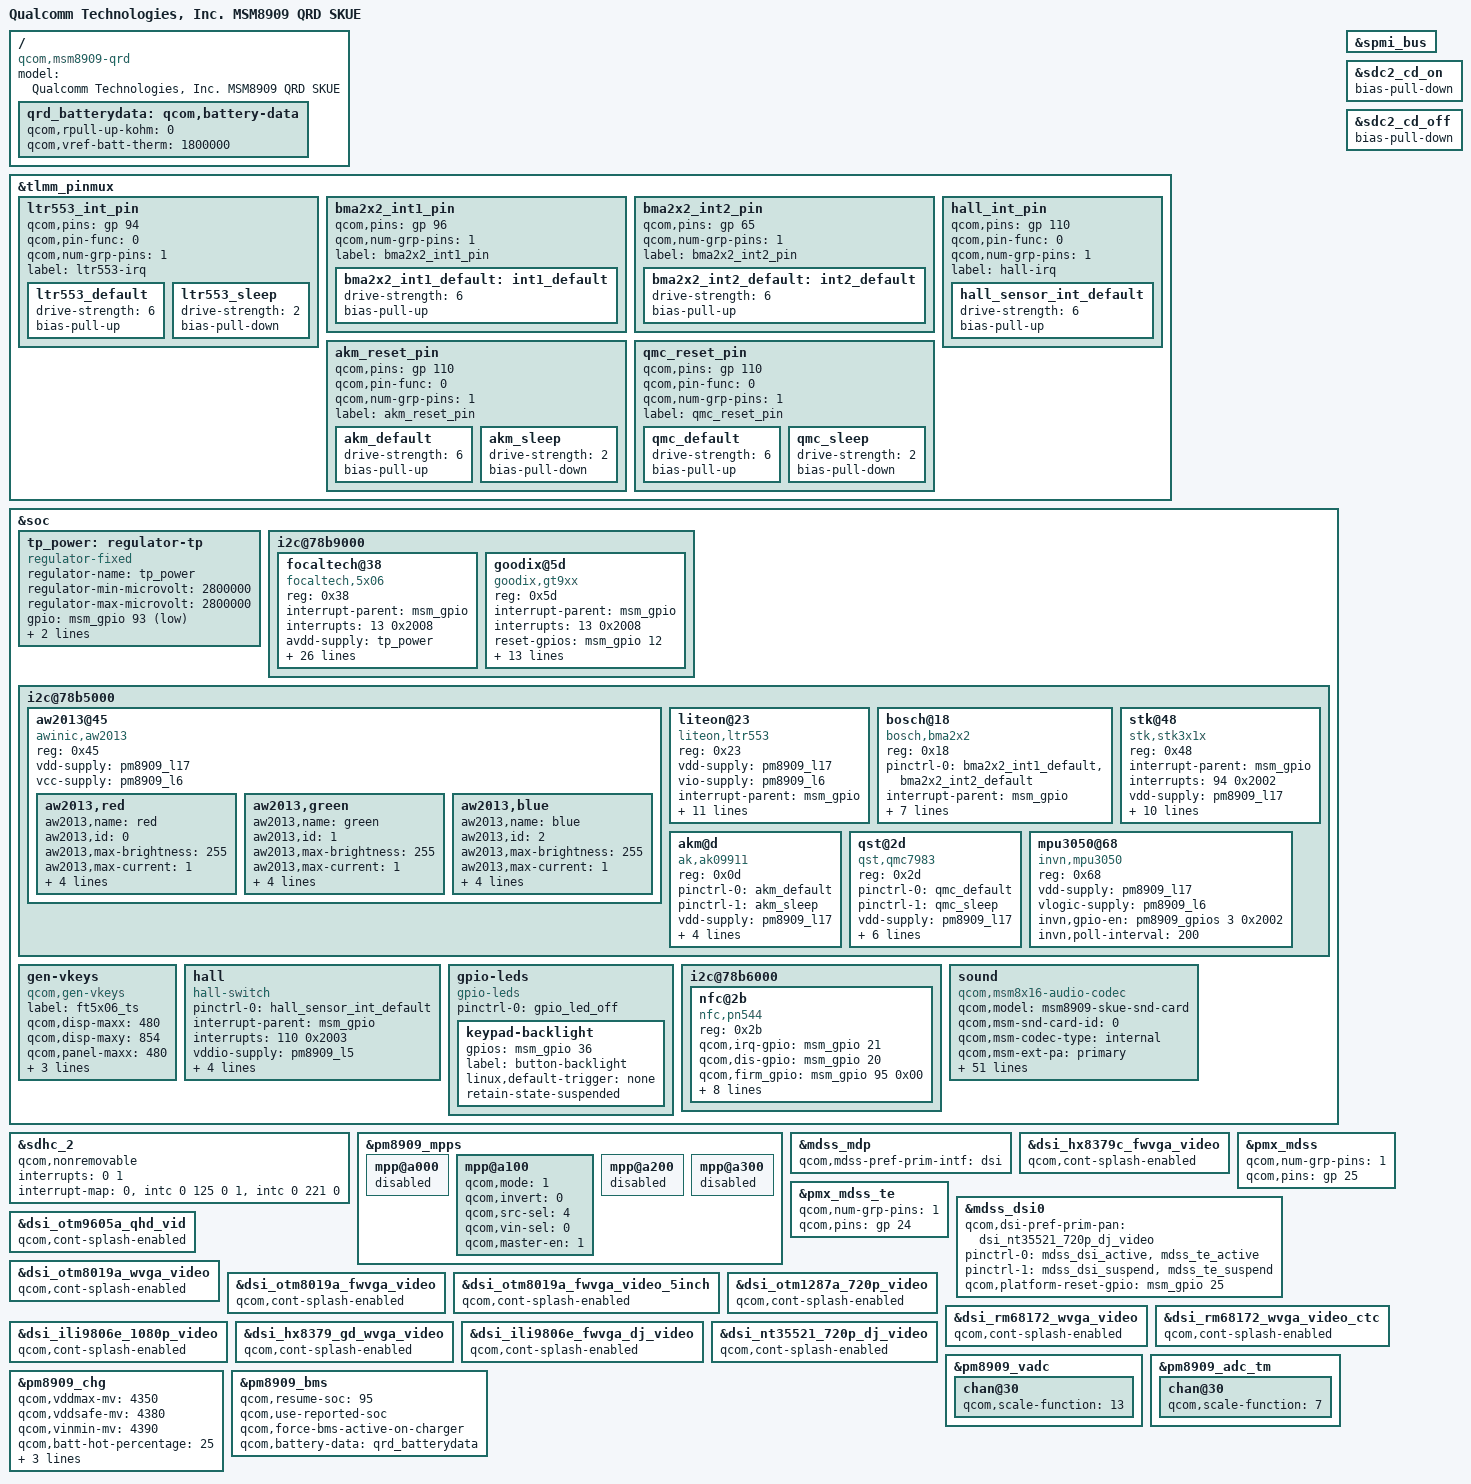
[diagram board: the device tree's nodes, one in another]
/**********uniscope-driver-modify-file-on-qualcomm-platform*****************/
/* Copyright (c) 2014-2015, The Linux Foundation. All rights reserved.
 *
 * This program is free software; you can redistribute it and/or modify
 * it under the terms of the GNU General Public License version 2 and
 * only version 2 as published by the Free Software Foundation.
 *
 * This program is distributed in the hope that it will be useful,
 * but WITHOUT ANY WARRANTY; without even the implied warranty of
 * MERCHANTABILITY or FITNESS FOR A PARTICULAR PURPOSE.  See the
 * GNU General Public License for more details.
 */

#include "msm8909-qrd.dtsi"
#include "msm8909-camera-sensor-skue.dtsi"

/ {
	model = "Qualcomm Technologies, Inc. MSM8909 QRD SKUE";
	compatible = "qcom,msm8909-qrd", "qcom,msm8909", "qcom,qrd";
};

&tlmm_pinmux {
	ltr553_int_pin {
		qcom,pins = <&gp 94>;
		qcom,pin-func = <0>;
		qcom,num-grp-pins = <1>;
		label = "ltr553-irq";
		ltr553_default: ltr553_default {
			drive-strength = <6>;
			bias-pull-up;
		};
		ltr553_sleep: ltr553_sleep {
			drive-strength = <2>;
			bias-pull-down;
		};

	};

	bma2x2_int1_pin {
		qcom,pins = <&gp 96>;
		qcom,num-grp-pins = <1>;
		label = "bma2x2_int1_pin";
		bma2x2_int1_default: int1_default {
			  drive-strength = <6>;
			  bias-pull-up;
		};
	};

	bma2x2_int2_pin {
		qcom,pins = <&gp 65>;
		qcom,num-grp-pins = <1>;
		label = "bma2x2_int2_pin";
		bma2x2_int2_default: int2_default {
			  drive-strength = <6>;
			  bias-pull-up;
		};
	};

	hall_int_pin {
		qcom,pins = <&gp 110>; /* JZZ(zhizhang)@uniscope_drv for keyled use gpio36 20150210 */
		qcom,pin-func = <0>;
		qcom,num-grp-pins = <1>;
		label = "hall-irq";
		hall_sensor_int_default: hall_sensor_int_default {
			drive-strength = <6>;
			bias-pull-up;
		};
	};
	/* Added by JZZ(zhizhang)@uniscope_drv for sensor device tree 20150210 begin */
	akm_reset_pin {
		qcom,pins = <&gp 110>;
		qcom,pin-func = <0>;
		qcom,num-grp-pins = <1>;
		label = "akm_reset_pin";
		akm_default: akm_default {
			drive-strength = <6>;
			bias-pull-up;
		};
		akm_sleep: akm_sleep {
			drive-strength = <2>;
			bias-pull-down;
		};
	};
	/* Added by JZZ(zhizhang)@uniscope_drv for sensor device tree 20150210 end */
	/*kangyan@uni_drv add qmc7983 sleep protect begin*/
	qmc_reset_pin {
		qcom,pins = <&gp 110>;
		qcom,pin-func = <0>;
		qcom,num-grp-pins = <1>;
		label = "qmc_reset_pin";
		qmc_default: qmc_default {
			drive-strength = <6>;
			bias-pull-up;
		};
		qmc_sleep: qmc_sleep {
			drive-strength = <2>;
			bias-pull-down;
		};
	};
	/*kangyan@uni_drv add qmc7983 sleep protect end*/
};

&soc {
	/* <JZZ(zhizhang)>@uniscope_drv 20140701 for adding TP tp_power begin */
	tp_power: regulator-tp {
		compatible = "regulator-fixed";
		regulator-name = "tp_power";
		regulator-min-microvolt = <2800000>;
		regulator-max-microvolt = <2800000>;
		gpio = <&msm_gpio 93 0x01>;
		startup-delay-us = <20000>;
		enable-active-high;
	};
	/* <JZZ(zhizhang)>@uniscope_drv 20140701 for adding TP tp_power end */
	i2c@78b9000 { /* BLSP1 QUP5 */
		focaltech@38 {
				compatible = "focaltech,5x06";
				reg = <0x38>;
				interrupt-parent = <&msm_gpio>; 
				interrupts = <13 0x2008>;  
				avdd-supply =<&tp_power>;
				/*liguowei@uni	20150107  pinctrl  used by touchscreen begin */
				pinctrl-names = "pmx_ts_active","pmx_ts_suspend","pmx_ts_release";
				pinctrl-0 = <&ts_int_active &ts_reset_active>;
				pinctrl-1 = <&ts_int_suspend &ts_reset_suspend>;
				pinctrl-2 = <&ts_release>;
				/*liguowei@uni	20150107  pinctrl  used by touchscreen end */
				focaltech,name = "FT5406DQ9";
				focaltech,family-id = <0x55>;
				focaltech,reset-gpio = <&msm_gpio 12 0x0>;
				focaltech,irq-gpio = <&msm_gpio 13 0x2008>;
				focaltech,display-coords = <0 0 480 854>;
				focaltech,panel-coords = <0 0 500 854>;
				focaltech,button-map= <139 172 158>;
				focaltech,no-force-update;
				focaltech,i2c-pull-up;
				focaltech,fw-vkey-support;
				focaltech,group-id = <1>;
				focaltech,hard-reset-delay-ms = <20>;
				focaltech,soft-reset-delay-ms = <150>;
				focaltech,num-max-touches = <5>;
				focaltech,fw-name = "ft_8916_qrd_fw.bin";
				focaltech,fw-delay-aa-ms = <50>;
				focaltech,fw-delay-55-ms = <30>;
				focaltech,fw-upgrade-id1 = <0x79>;
				focaltech,fw-upgrade-id2 = <0x03>;
				focaltech,fw-delay-readid-ms = <10>;
				focaltech,fw-delay-era-flsh-ms = <2000>;
				focaltech,fw-auto-cal;
				focaltech,ignore-id-check;
			};

		
	/* JZZ(zhizhang)@uniscope_drv 20150206 add tp dtsi begin */
		goodix@5d {
			compatible = "goodix,gt9xx";
			reg = <0x5d>;
			interrupt-parent = <&msm_gpio>; 
			interrupts = <13 0x2008>;  
			reset-gpios = <&msm_gpio 12 0x00>;
			interrupt-gpios = <&msm_gpio 13 0x00>;
			avdd-supply =<&tp_power>;
			/*zhangbing@uniscope_drv20151013 TP gt9157 interrupt voltage abnormal(lower than normal) begin*/
			pinctrl-names = "pmx_ts_active","pmx_ts_suspend";
			pinctrl-0 = <&ts_int_active &ts_reset_active>;
			pinctrl-1 = <&ts_int_suspend &ts_reset_suspend>;
			/*zhangbing@uniscope_drv20151013 TP gt9157 interrupt voltage abnormal(lower than normal) end*/
			goodix,panel-coords = <0 0 480 854>;
			goodix,display-coords = <0 0 480 854>;
			goodix,button-map= <158 102 139>;
			goodix,product-id = "915";
			goodix,cfg-data0 = [
				41 E0 01 20 03 0A 05 C1 01 08 
				28 05 50 32 03 05 00 00 FF 7F 
				00 00 00 00 00 00 14 88 27 0A 
				2C 2E B5 06 00 00 01 9B 33 11 
				3C 01 00 00 00 03 64 32 00 00 
				CA 1E 5A 94 C5 02 07 00 00 04 
				A8 21 00 88 29 00 6D 34 00 58 
				41 00 48 51 00 48 0F 2F 47 00 
				F7 40 30 FF FF 27 00 00 00 00 
				00 00 00 00 00 00 00 00 00 00 
				00 00 00 00 00 00 00 19 00 00 
				46 00 08 0A 0C 0E 10 12 14 16 
				18 1A 00 00 00 00 00 00 00 00 
				00 00 00 00 00 00 00 00 00 00 
				00 00 28 24 22 20 1F 1E 1D 0C 
				0A 08 06 05 04 02 00 00 00 00 
				00 00 00 00 00 00 00 00 00 00 
				00 FF FF FF FF FF FF FF FF FF 
				FF FF FF FF B4 01];
			goodix,cfg-data1 = [
				41 E0 01 20 03 0A 05 C1 01 08 
				28 05 50 32 03 05 00 00 FF 7F 
				00 00 00 00 00 00 14 88 27 0A 
				2C 2E B5 06 00 00 01 9B 33 11 
				3C 01 00 00 00 03 64 32 00 00 
				CA 1E 5A 94 C5 02 07 00 00 04 
				A8 21 00 88 29 00 6D 34 00 58 
				41 00 48 51 00 48 0F 2F 47 00 
				F7 40 30 FF FF 27 00 00 00 00 
				00 00 00 00 00 00 00 00 00 00 
				00 00 00 00 00 00 00 19 00 00 
				46 00 08 0A 0C 0E 10 12 14 16 
				18 1A 00 00 00 00 00 00 00 00 
				00 00 00 00 00 00 00 00 00 00 
				00 00 28 24 22 20 1F 1E 1D 0C 
				0A 08 06 05 04 02 00 00 00 00 
				00 00 00 00 00 00 00 00 00 00 
				00 FF FF FF FF FF FF FF FF FF 
				FF FF FF FF B4 01];
			goodix,fw_name = "gtp_fw.bin";
		};
	/* JZZ(zhizhang)@uniscope_drv 20150206 add TP dtsi end */		
	};

	i2c@78b5000 { /* BLSP1 QUP1 */
		aw2013@45 {
			compatible = "awinic,aw2013";
			reg = <0x45>;
			vdd-supply = <&pm8909_l17>;
			vcc-supply = <&pm8909_l6>;

			aw2013,red {
				aw2013,name = "red";
				aw2013,id = <0>;
				aw2013,max-brightness = <255>;
				aw2013,max-current = <1>;
				aw2013,rise-time-ms = <2>;
				aw2013,hold-time-ms = <1>;
				aw2013,fall-time-ms = <2>;
				aw2013,off-time-ms = <1>;
			};

			aw2013,green {
				aw2013,name = "green";
				aw2013,id = <1>;
				aw2013,max-brightness = <255>;
				aw2013,max-current = <1>;
				aw2013,rise-time-ms = <2>;
				aw2013,hold-time-ms = <1>;
				aw2013,fall-time-ms = <2>;
				aw2013,off-time-ms = <1>;
			};

			aw2013,blue {
				aw2013,name = "blue";
				aw2013,id = <2>;
				aw2013,max-brightness = <255>;
				aw2013,max-current = <1>;
				aw2013,rise-time-ms = <2>;
				aw2013,hold-time-ms = <1>;
				aw2013,fall-time-ms = <2>;
				aw2013,off-time-ms = <1>;
			};
		};
	};

	gen-vkeys {
		compatible = "qcom,gen-vkeys";
		label = "ft5x06_ts";
		qcom,disp-maxx = <480>;
		qcom,disp-maxy = <854>;
		qcom,panel-maxx = <480>;
		qcom,panel-maxy = <946>;
		qcom,key-codes = <139 172 158>;
		qcom,y-offset = <0>;
	};

	i2c@78b5000 { /* BLSP1 QUP1 */
		liteon@23 {
			compatible = "liteon,ltr553";
			reg = <0x23>;
			vdd-supply = <&pm8909_l17>;
			vio-supply = <&pm8909_l6>;
			interrupt-parent = <&msm_gpio>;
			interrupts = <94 0x2002>;
			pinctrl-names = "default","sleep";
			pinctrl-0 = <&ltr553_default>;
			pinctrl-1 = <&ltr553_sleep>;
			liteon,irq-gpio = <&msm_gpio 94 0x2002>;
			liteon,als-ps-persist = <0>;
			liteon,ps-led = <0x7f>;
			liteon,ps-pulses = <4>;
			liteon,wakeup-threshold = <4>;
			liteon,als-integration-time = <0>;
			liteon,ps-distance-table = <1376 566 343 287 200 170 155>;
		};

		bosch@18 { /* Accelerometer sensor */
			compatible = "bosch,bma2x2";
			reg = <0x18>;
			pinctrl-names = "default";
			pinctrl-0 = <&bma2x2_int1_default &bma2x2_int2_default>;
			interrupt-parent = <&msm_gpio>;
			interrupts = <96 0x2002>;
			vdd-supply = <&pm8909_l17>;
			vio-supply = <&pm8909_l6>;
			bosch,init-interval = <200>;
			bosch,place = <4>;
			bosch,gpio-int1 = <&msm_gpio 96 0x2002>;
			bosch,gpio-int2 = <&msm_gpio 65 0x2002>;
		};

		/*liguowei@uniscope 20140910 add stk3x1x begin*/
		stk@48 {
			compatible = "stk,stk3x1x";
			reg = <0x48>;
			interrupt-parent = <&msm_gpio>;
			interrupts = <94 0x2002>;
			vdd-supply = <&pm8909_l17>;
			vio-supply = <&pm8909_l6>;
			stk,irq-gpio = <&msm_gpio 94 0x2002>;
			stk,transmittance = <4092>;
			stk,state-reg = <0x00>;
			stk,psctrl-reg = <0x31>;
			stk,alsctrl-reg = <0x39>;
			stk,ledctrl-reg = <0xBF>;
			stk,wait-reg = <0x09>;
			stk,ps-thdh = <100>;
			stk,ps-thdl = <50>;
		};
		//liguowei@uniscope 20140910 add stk3x1x end	
		/* Added by JZZ(zhizhang)@uniscope_drv for sensor device tree 20150210 begin */
		akm@d {
			compatible = "ak,ak09911";
			reg = <0x0d>;
			pinctrl-names = "default","sleep";
			pinctrl-0 = <&akm_default>;
			pinctrl-1 = <&akm_sleep>;
			vdd-supply = <&pm8909_l17>;
			vio-supply = <&pm8909_l6>;
			akm,layout = <0x5>;
			akm,gpio_rstn = <&msm_gpio 99 0x0>;
			akm,auto-report;
		};
		//kangyan@uniscope_drv add QMC7983 sensor 20150511
		qst@2d { /* Magnetic field sensor */
			compatible = "qst,qmc7983";
			reg = <0x2d>;
			pinctrl-names = "default","sleep";
			pinctrl-0 = <&qmc_default>;
			pinctrl-1 = <&qmc_sleep>;
			vdd-supply = <&pm8909_l17>;
			vio-supply = <&pm8909_l6>;
			qst,dir = "obverse-x-axis-forward";
			qst,gpio_rstn = <&msm_gpio 110 0x0>;
			qst,layout = <0x8>;
			qst,auto-report;
			qst,delay_ms = <10>;
		};
		mpu3050@68 { /* Gyroscope and accelerometer sensor combo */
			compatible = "invn,mpu3050";
			reg = <0x68>;		
			vdd-supply = <&pm8909_l17>;
			vlogic-supply = <&pm8909_l6>;
			invn,gpio-en = <&pm8909_gpios 3 0x2002>;
			invn,poll-interval = <200>;
		};
		/* Added by JZZ(zhizhang)@uniscope_drv for sensor device tree 20150210 end */
	};

	hall {
		compatible = "hall-switch";
		pinctrl-names = "default";
		pinctrl-0 = <&hall_sensor_int_default>;
		interrupt-parent = <&msm_gpio>;
		interrupts = <110 0x2003>;   /* JZZ(zhizhang)@uniscope_drv for keyled use gpio36 20150210 */
		vddio-supply = <&pm8909_l5>;
		linux,gpio-int = <&msm_gpio 110 0x1>;  /* JZZ(zhizhang)@uniscope_drv for keyled use gpio36 20150210 */
		linux,wakeup;
		linux,min-uv = <1650000>;
		linux,max-uv = <3300000>;
	};
	
	/* JZZ(zhizhang)@uniscope_drv 20150317 add keypad led control begin */
	gpio-leds {
		compatible = "gpio-leds";
		status = "okay";
		pinctrl-names = "default";
		pinctrl-0 = <&gpio_led_off>;

		keypad-backlight {
			gpios = <&msm_gpio 36 0>;
			label = "button-backlight";
			linux,default-trigger = "none";
			retain-state-suspended;
		};
	};
	/* JZZ(zhizhang)@uniscope_drv 20150317 add keypad led control end */

	//JZZ(zhizhang)@uni_drv 20150410 add nfc pn547 driver begin 
	i2c@78b6000 { /* BLSP1 QUP2 */
		nfc@2b {
			compatible = "nfc,pn544";
			reg = <0x2b>;
			qcom,irq-gpio = <&msm_gpio 21 0x00>;
			qcom,dis-gpio = <&msm_gpio 20 0x00>;
			qcom,firm_gpio= <&msm_gpio 95 0x00>;
			qcom,clk-src = "BBCLK2";
			interrupt-parent = <&msm_gpio>;
			interrupts = <21 0>;
			interrupt-names = "nfc_irq";
			pinctrl-names = "nfc_active","nfc_suspend";
			pinctrl-0 = <&nfc_int_active &nfc_disable_active>;
			pinctrl-1 = <&nfc_int_suspend &nfc_disable_suspend>;
			qcom,clk-gpio = <&pm8909_gpios 2 0>;
			clocks = <&clock_rpm clk_bb_clk2_pin>;
			clock-names = "ref_clk";
		};
	};
	//JZZ(zhizhang)@uni_drv 20150410 add nfc pn547 driver end

	sound {
		compatible = "qcom,msm8x16-audio-codec";
		qcom,model = "msm8909-skue-snd-card";
		qcom,msm-snd-card-id = <0>;
		qcom,msm-codec-type = "internal";
		qcom,msm-ext-pa = "primary";
		qcom,msm-mclk-freq = <9600000>;
		//kangyan@uni_drv 20150319 enable spk and micbias
		qcom,msm-spk-ext-pa = <&msm_gpio 98 0>;
		qcom,msm-mbhc-hphl-swh = <1>;
		qcom,msm-mbhc-gnd-swh = <0>;
		qcom,msm-hs-micbias-type = "internal";
		qcom,msm-micbias1-ext-cap;
		qcom,msm-micbias2-ext-cap;
		qcom,audio-routing =
			"RX_BIAS", "MCLK",
			"SPK_RX_BIAS", "MCLK",
			"INT_LDO_H", "MCLK",
			"MIC BIAS Internal1", "Handset Mic",
			"MIC BIAS Internal2", "Headset Mic",
			"MIC BIAS Internal3", "Secondary Mic",
			"AMIC1", "MIC BIAS Internal1",
			"AMIC2", "MIC BIAS Internal2",
			"AMIC3", "MIC BIAS Internal3";			
		pinctrl-names = "cdc_lines_act",
				"cdc_lines_sus";
		pinctrl-0 = <&cdc_pdm_lines_act>;
		pinctrl-1 = <&cdc_pdm_lines_sus>;
		asoc-platform = <&pcm0>, <&pcm1>, <&voip>, <&voice>,
				<&loopback>, <&compress>, <&hostless>,
				<&afe>, <&lsm>, <&routing>, <&lpa>,
				<&voice_svc>;
		asoc-platform-names = "msm-pcm-dsp.0", "msm-pcm-dsp.1",
				"msm-voip-dsp", "msm-pcm-voice", "msm-pcm-loopback",
				"msm-compress-dsp", "msm-pcm-hostless", "msm-pcm-afe",
				"msm-lsm-client", "msm-pcm-routing", "msm-pcm-lpa",
				"msm-voice-svc";
		asoc-cpu = <&dai_pri_auxpcm>, <&dai_hdmi>,
				<&dai_mi2s0>, <&dai_mi2s1>, <&dai_mi2s2>, <&dai_mi2s3>,
				<&sb_0_rx>, <&sb_0_tx>, <&sb_1_rx>, <&sb_1_tx>,
				<&sb_3_rx>, <&sb_3_tx>, <&sb_4_rx>, <&sb_4_tx>,
				<&bt_sco_rx>, <&bt_sco_tx>, <&int_fm_rx>, <&int_fm_tx>,
				<&afe_pcm_rx>, <&afe_pcm_tx>, <&afe_proxy_rx>, <&afe_proxy_tx>,
				<&incall_record_rx>, <&incall_record_tx>, <&incall_music_rx>,
				<&incall_music_2_rx>;
		asoc-cpu-names = "msm-dai-q6-auxpcm.1", "msm-dai-q6-hdmi.8",
				"msm-dai-q6-mi2s.0", "msm-dai-q6-mi2s.1",
				"msm-dai-q6-mi2s.2", "msm-dai-q6-mi2s.3",
				"msm-dai-q6-dev.16384",	"msm-dai-q6-dev.16385",
				"msm-dai-q6-dev.16386", "msm-dai-q6-dev.16387",
				"msm-dai-q6-dev.16390", "msm-dai-q6-dev.16391",
				"msm-dai-q6-dev.16392",	"msm-dai-q6-dev.16393",
				"msm-dai-q6-dev.12288", "msm-dai-q6-dev.12289",
				"msm-dai-q6-dev.12292", "msm-dai-q6-dev.12293",
				"msm-dai-q6-dev.224", "msm-dai-q6-dev.225",
				"msm-dai-q6-dev.241", "msm-dai-q6-dev.240",
				"msm-dai-q6-dev.32771", "msm-dai-q6-dev.32772",
				"msm-dai-q6-dev.32773", "msm-dai-q6-dev.32770";
		asoc-codec = <&stub_codec>, <&pm8909_conga_dig>;
		asoc-codec-names = "msm-stub-codec.1", "tombak_codec";
	};
};

&spmi_bus {
	/* JZZ(zhizhang)@uniscope_drv 20150317 add keypad led control begin */
	/*
	qcom,pm8909@0 {
		qcom,leds@a300 {
			status = "okay";
			qcom,led_mpp_4 {
				label = "mpp";
				linux,name = "button-backlight";
				linux,default-trigger = "none";
				qcom,default-state = "off";
				qcom,max-current = <40>;
				qcom,current-setting = <5>;
				qcom,id = <6>;
				qcom,mode = "manual";
				qcom,source-sel = <1>;
				qcom,mode-ctrl = <0x60>;
			};
		};
	};
	*/
	/* JZZ(zhizhang)@uniscope_drv 20150317 add keypad led control end */
};

&sdc2_cd_on {
        /delete-property/ bias-pull-up;
        bias-pull-down;
};

&sdc2_cd_off {
        /delete-property/ bias-disable;
        bias-pull-down;
};

&sdhc_2 {
        qcom,nonremovable;

        interrupts = <0 1>;
        interrupt-map = <0 &intc 0 125 0
                1 &intc 0 221 0>;
        interrupt-names = "hc_irq", "pwr_irq";
        /delete-property/ cd-gpios;
};

&pm8909_mpps {
	mpp@a000 { /* MPP 1 */
		/* VDD_PX */
		status = "disabled";
	};

	mpp@a100 { /* MPP 2 */
		/* Backlight PWM */
		qcom,mode = <1>;		/* Digital output */
		qcom,invert = <0>;		/* Disable invert */
		qcom,src-sel = <4>;		/* DTEST1 */
		qcom,vin-sel = <0>;		/* VPH_PWR */
		qcom,master-en = <1>;		/* Enable MPP */
	};

	mpp@a200 { /* MPP 3 */
		/* VREF DAC */
		status = "disabled";
	};

	mpp@a300 { /* MPP 4 */
		/* HR LED */
		status = "disabled";
	};
};

#include "dsi-panel-hx8379c-fwvga-video.dtsi"

&mdss_mdp {
	qcom,mdss-pref-prim-intf = "dsi";
};

&dsi_hx8379c_fwvga_video {
	qcom,cont-splash-enabled;
};

&pmx_mdss {
	qcom,num-grp-pins = <1>;
	qcom,pins = <&gp 25>;
};

&pmx_mdss_te {
	qcom,num-grp-pins = <1>;
	qcom,pins = <&gp 24>;
};

&mdss_dsi0 {
	qcom,dsi-pref-prim-pan = <&dsi_hx8379c_fwvga_video>;
	pinctrl-names = "mdss_default", "mdss_sleep";
	pinctrl-0 = <&mdss_dsi_active &mdss_te_active>;
	pinctrl-1 = <&mdss_dsi_suspend &mdss_te_suspend>;

	qcom,platform-reset-gpio = <&msm_gpio 25 0>;
};

/* JZZ(zhizhang)@uniscope_drv 20140620 for adjusting otm9605a-qhd lcd begin */
#include "dsi-panel-otm9605a-qhd-video.dtsi"
&mdss_mdp {
	qcom,mdss-pref-prim-intf = "dsi";
};

&dsi_otm9605a_qhd_vid {
	qcom,cont-splash-enabled;
};

&pmx_mdss {
	qcom,num-grp-pins = <1>;
	qcom,pins = <&gp 25>;
};

&pmx_mdss_te {
	qcom,num-grp-pins = <1>;
	qcom,pins = <&gp 24>;
};

&mdss_dsi0 {
	qcom,dsi-pref-prim-pan = <&dsi_otm9605a_qhd_vid>;
	pinctrl-names = "mdss_default", "mdss_sleep";
	pinctrl-0 = <&mdss_dsi_active &mdss_te_active>;
	pinctrl-1 = <&mdss_dsi_suspend &mdss_te_suspend>;

	qcom,platform-reset-gpio = <&msm_gpio 25 0>;
};

#include "dsi-panel-otm8019a-wvga-video.dtsi"
&mdss_mdp {
	qcom,mdss-pref-prim-intf = "dsi";
};

&dsi_otm8019a_wvga_video {
	qcom,cont-splash-enabled;
};

&pmx_mdss {
	qcom,num-grp-pins = <1>;
	qcom,pins = <&gp 25>;
};

&pmx_mdss_te {
	qcom,num-grp-pins = <1>;
	qcom,pins = <&gp 24>;
};

&mdss_dsi0 {
	qcom,dsi-pref-prim-pan = <&dsi_otm8019a_wvga_video>;
	pinctrl-names = "mdss_default", "mdss_sleep";
	pinctrl-0 = <&mdss_dsi_active &mdss_te_active>;
	pinctrl-1 = <&mdss_dsi_suspend &mdss_te_suspend>;

	qcom,platform-reset-gpio = <&msm_gpio 25 0>;
};

/*zhangbing@uniscope drv 20150624 add L510 LCD OTM8019A FWVGA begin*/
#include "dsi-panel-otm8019a-fwvga-video.dtsi"
&mdss_mdp {
	qcom,mdss-pref-prim-intf = "dsi";
};

&dsi_otm8019a_fwvga_video {
	qcom,cont-splash-enabled;
};

&pmx_mdss {
	qcom,num-grp-pins = <1>;
	qcom,pins = <&gp 25>;
};

&pmx_mdss_te {
	qcom,num-grp-pins = <1>;
	qcom,pins = <&gp 24>;
};

&mdss_dsi0 {
	qcom,dsi-pref-prim-pan = <&dsi_otm8019a_fwvga_video>;
	pinctrl-names = "mdss_default", "mdss_sleep";
	pinctrl-0 = <&mdss_dsi_active &mdss_te_active>;
	pinctrl-1 = <&mdss_dsi_suspend &mdss_te_suspend>;

	qcom,platform-reset-gpio = <&msm_gpio 25 0>;
};
/*zhangbing@uniscope drv 20150624 add L510 LCD OTM8019A FWVGA end*/

/*zhangbing@uniscope drv 20150624 add L510 LCD OTM8019A FWVGA 5INCH begin*/
#include "dsi-panel-otm8019a-fwvga-video-5inch.dtsi"
&mdss_mdp {
	qcom,mdss-pref-prim-intf = "dsi";
};

&dsi_otm8019a_fwvga_video_5inch {
	qcom,cont-splash-enabled;
};

&pmx_mdss {
	qcom,num-grp-pins = <1>;
	qcom,pins = <&gp 25>;
};

&pmx_mdss_te {
	qcom,num-grp-pins = <1>;
	qcom,pins = <&gp 24>;
};

&mdss_dsi0 {
	qcom,dsi-pref-prim-pan = <&dsi_otm8019a_fwvga_video_5inch>;
	pinctrl-names = "mdss_default", "mdss_sleep";
	pinctrl-0 = <&mdss_dsi_active &mdss_te_active>;
	pinctrl-1 = <&mdss_dsi_suspend &mdss_te_suspend>;

	qcom,platform-reset-gpio = <&msm_gpio 25 0>;
};
/*zhangbing@uniscope drv 20150624 add L510 LCD OTM8019A FWVGA 5INCH end*/

/*zhangbing@uniscope drv 20150624 add L510 LCD OTM1287A 720p begin*/
#include "dsi-panel-otm1287a-720p-video.dtsi"
&mdss_mdp {
	qcom,mdss-pref-prim-intf = "dsi";
};

&dsi_otm1287a_720p_video {
	qcom,cont-splash-enabled;
};

&pmx_mdss {
	qcom,num-grp-pins = <1>;
	qcom,pins = <&gp 25>;
};

&pmx_mdss_te {
	qcom,num-grp-pins = <1>;
	qcom,pins = <&gp 24>;
};

&mdss_dsi0 {
	qcom,dsi-pref-prim-pan = <&dsi_otm1287a_720p_video>;
	pinctrl-names = "mdss_default", "mdss_sleep";
	pinctrl-0 = <&mdss_dsi_active &mdss_te_active>;
	pinctrl-1 = <&mdss_dsi_suspend &mdss_te_suspend>;

	qcom,platform-reset-gpio = <&msm_gpio 25 0>;
};
/*zhangbing@uniscope drv 20150624 add L510 LCD OTM1287A 720p end*/

#include "dsi-panel-rm68172-wvga-video.dtsi"
&mdss_mdp {
	qcom,mdss-pref-prim-intf = "dsi";
};

&dsi_rm68172_wvga_video {
	qcom,cont-splash-enabled;
};

&pmx_mdss {
	qcom,num-grp-pins = <1>;
	qcom,pins = <&gp 25>;
};

&pmx_mdss_te {
	qcom,num-grp-pins = <1>;
	qcom,pins = <&gp 24>;
};

&mdss_dsi0 {
	qcom,dsi-pref-prim-pan = <&dsi_rm68172_wvga_video>;
	pinctrl-names = "mdss_default", "mdss_sleep";
	pinctrl-0 = <&mdss_dsi_active &mdss_te_active>;
	pinctrl-1 = <&mdss_dsi_suspend &mdss_te_suspend>;

	qcom,platform-reset-gpio = <&msm_gpio 25 0>;
};


#include "dsi-panel-rm68172-wvga-video_ctc.dtsi"
&mdss_mdp {
	qcom,mdss-pref-prim-intf = "dsi";
};

&dsi_rm68172_wvga_video_ctc {
	qcom,cont-splash-enabled;
};

&pmx_mdss {
	qcom,num-grp-pins = <1>;
	qcom,pins = <&gp 25>;
};

&pmx_mdss_te {
	qcom,num-grp-pins = <1>;
	qcom,pins = <&gp 24>;
};

&mdss_dsi0 {
	qcom,dsi-pref-prim-pan = <&dsi_rm68172_wvga_video_ctc>;
	pinctrl-names = "mdss_default", "mdss_sleep";
	pinctrl-0 = <&mdss_dsi_active &mdss_te_active>;
	pinctrl-1 = <&mdss_dsi_suspend &mdss_te_suspend>;

	qcom,platform-reset-gpio = <&msm_gpio 25 0>;
};

#include "dsi-panel-ILI9806E-wvga-video.dtsi"
&mdss_mdp {
	qcom,mdss-pref-prim-intf = "dsi";
};

&dsi_ili9806e_1080p_video {
	qcom,cont-splash-enabled;
};

&pmx_mdss {
	qcom,num-grp-pins = <1>;
	qcom,pins = <&gp 25>;
};

&pmx_mdss_te {
	qcom,num-grp-pins = <1>;
	qcom,pins = <&gp 24>;
};

&mdss_dsi0 {
	qcom,dsi-pref-prim-pan = <&dsi_ili9806e_1080p_video>;
	pinctrl-names = "mdss_default", "mdss_sleep";
	pinctrl-0 = <&mdss_dsi_active &mdss_te_active>;
	pinctrl-1 = <&mdss_dsi_suspend &mdss_te_suspend>;

	qcom,platform-reset-gpio = <&msm_gpio 25 0>;
};

#include "dsi-panel-hx8379-gd_wvga-video.dtsi"
&mdss_mdp {
	qcom,mdss-pref-prim-intf = "dsi";
};

&dsi_hx8379_gd_wvga_video {
	qcom,cont-splash-enabled;
};

&pmx_mdss {
	qcom,num-grp-pins = <1>;
	qcom,pins = <&gp 25>;
};

&pmx_mdss_te {
	qcom,num-grp-pins = <1>;
	qcom,pins = <&gp 24>;
};

&mdss_dsi0 {
	qcom,dsi-pref-prim-pan = <&dsi_hx8379_gd_wvga_video>;
	pinctrl-names = "mdss_default", "mdss_sleep";
	pinctrl-0 = <&mdss_dsi_active &mdss_te_active>;
	pinctrl-1 = <&mdss_dsi_suspend &mdss_te_suspend>;

	qcom,platform-reset-gpio = <&msm_gpio 25 0>;
};
/* JZZ(zhizhang)@uniscope_drv 20140620 for adjusting otm9605a-qhd lcd end */

/*zhangbing@uniscope_drv 20150619 add L511 LCD ili9806e fwvga begin*/
#include "dsi-panel-ILI9806E-fwvga-dj-video.dtsi"
&mdss_mdp {
	qcom,mdss-pref-prim-intf = "dsi";
};

&dsi_ili9806e_fwvga_dj_video {
	qcom,cont-splash-enabled;
};

&pmx_mdss {
	qcom,num-grp-pins = <1>;
	qcom,pins = <&gp 25>;
};

&pmx_mdss_te {
	qcom,num-grp-pins = <1>;
	qcom,pins = <&gp 24>;
};

&mdss_dsi0 {
	qcom,dsi-pref-prim-pan = <&dsi_ili9806e_fwvga_dj_video>;
	pinctrl-names = "mdss_default", "mdss_sleep";
	pinctrl-0 = <&mdss_dsi_active &mdss_te_active>;
	pinctrl-1 = <&mdss_dsi_suspend &mdss_te_suspend>;

	qcom,platform-reset-gpio = <&msm_gpio 25 0>;
};
/*zhangbing@uniscope_drv 20150619 add L511 LCD ili9806e fwvga end*/

/*zhangbing@uniscope_drv 20150906 add L510 LCD nt35521 720p begin*/
#include "dsi-panel-nt35521-720p-dj-video.dtsi"
&mdss_mdp {
	qcom,mdss-pref-prim-intf = "dsi";
};

&dsi_nt35521_720p_dj_video {
	qcom,cont-splash-enabled;
};

&pmx_mdss {
	qcom,num-grp-pins = <1>;
	qcom,pins = <&gp 25>;
};

&pmx_mdss_te {
	qcom,num-grp-pins = <1>;
	qcom,pins = <&gp 24>;
};

&mdss_dsi0 {
	qcom,dsi-pref-prim-pan = <&dsi_nt35521_720p_dj_video>;
	pinctrl-names = "mdss_default", "mdss_sleep";
	pinctrl-0 = <&mdss_dsi_active &mdss_te_active>;
	pinctrl-1 = <&mdss_dsi_suspend &mdss_te_suspend>;

	qcom,platform-reset-gpio = <&msm_gpio 25 0>;
};
/*zhangbing@uniscope_drv 20150906 add L510 LCD nt35521 720p end*/

&pm8909_vadc {
	chan@30 {
		qcom,scale-function = <13>;
	};
};


&pm8909_adc_tm {
	chan@30 {
		qcom,scale-function = <7>;
	};
};

&pm8909_chg {
	qcom,vddmax-mv = <4350>;
	qcom,vddsafe-mv = <4380>;
	qcom,vinmin-mv = <4390>; /* uni@fantian for charger 20150715 */
	qcom,batt-hot-percentage = <25>;
	qcom,batt-cold-percentage = <80>;
	qcom,tchg-mins = <360>;
	qcom,disable-vbatdet-based-recharge;
	status = "okay";
};

/ {
	qrd_batterydata: qcom,battery-data {
		qcom,rpull-up-kohm = <0>;
		qcom,vref-batt-therm = <1800000>;

		#include "batterydata-uni-L500D-4v35-2500mah.dtsi"
	};
};

&pm8909_bms {
	status = "okay";
	qcom,resume-soc = <95>;
	qcom,use-reported-soc;
	qcom,force-bms-active-on-charger;
	qcom,battery-data = <&qrd_batterydata>;
};
